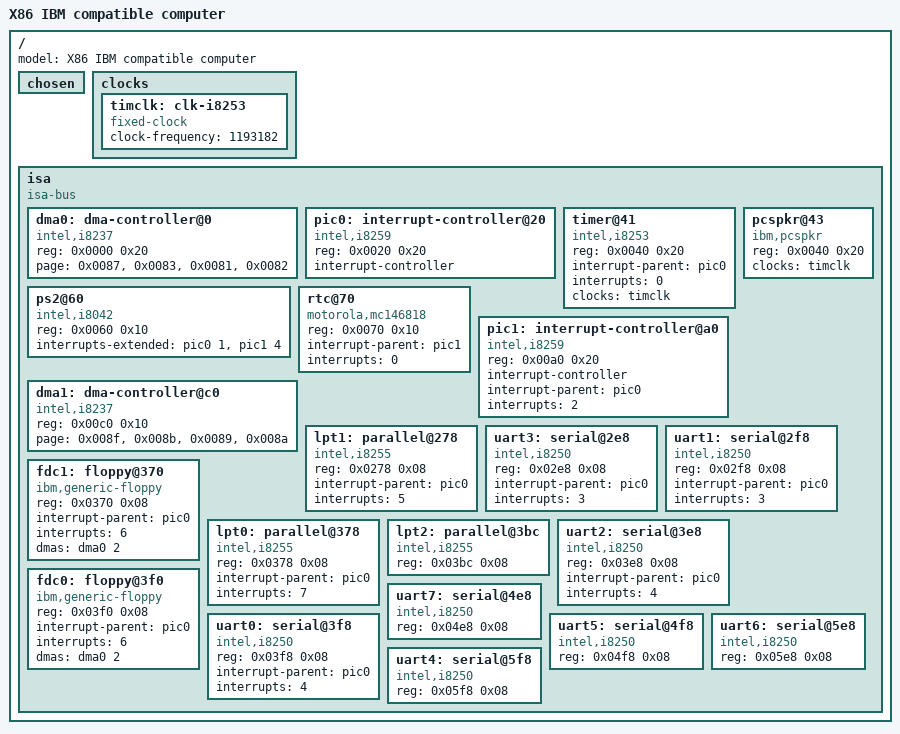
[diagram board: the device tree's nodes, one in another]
/* SPDX-License-Identifier: GPL-2.0-or-later */
/*
 * Copyright(c) 2021 John Sanpe <sanpeqf@gmail.com>
 */

/ {
    model = "X86 IBM compatible computer";
    #address-cells = <1>;
    #size-cells = <1>;

    chosen { };

    clocks {
        timclk: clk-i8253 {
            #clock-cells = <0>;
            compatible = "fixed-clock";
            clock-frequency = <1193182>;
        };
    };

    isa {
        #address-cells = <1>;
        #size-cells = <1>;
        compatible = "isa-bus";

        dma0: dma-controller@0 {
            #dma-cells = <1>;
            compatible = "intel,i8237";
            reg = <0x0000 0x20>;
            page = <0x0087>, <0x0083>,
                   <0x0081>, <0x0082>;
        };

        pic0: interrupt-controller@20 {
            #interrupt-cells = <1>;
            #address-cells = <0>;
            compatible = "intel,i8259";
            reg = <0x0020 0x20>;
            interrupt-controller;
        };

        timer@41 {
            compatible = "intel,i8253";
            reg = <0x0040 0x20>;
            interrupt-parent = <&pic0>;
            interrupts = <0>;
            clocks = <&timclk>;
        };

        pcspkr@43 {
            compatible = "ibm,pcspkr";
            reg = <0x0040 0x20>;
            clocks = <&timclk>;
        };

        ps2@60 {
            compatible = "intel,i8042";
            reg = <0x0060 0x10>;
            interrupt-names = "kbd", "aux";
            interrupts-extended = <&pic0 1>, <&pic1 4>;
        };

        rtc@70 {
            compatible = "motorola,mc146818";
            reg = <0x0070 0x10>;
            interrupt-parent = <&pic1>;
            interrupts = <0>;
        };

        pic1: interrupt-controller@a0 {
            #interrupt-cells = <1>;
            #address-cells = <0>;
            compatible = "intel,i8259";
            reg = <0x00a0 0x20>;
            interrupt-controller;
            interrupt-parent = <&pic0>;
            interrupts = <2>;
        };

        dma1: dma-controller@c0 {
            #dma-cells = <1>;
            compatible = "intel,i8237";
            reg = <0x00c0 0x10>;
            page = <0x008f>, <0x008b>,
                   <0x0089>, <0x008a>;
        };

        lpt1: parallel@278 {
            compatible = "intel,i8255";
            reg = <0x0278 0x08>;
            interrupt-parent = <&pic0>;
            interrupts = <5>;
            #address-cells = <1>;
            #size-cells = <0>;
        };

        uart3: serial@2e8 {
            compatible = "intel,i8250";
            reg = <0x02e8 0x08>;
            interrupt-parent = <&pic0>;
            interrupts = <3>;
        };

        uart1: serial@2f8 {
            compatible = "intel,i8250";
            reg = <0x02f8 0x08>;
            interrupt-parent = <&pic0>;
            interrupts = <3>;
        };

        fdc1: floppy@370 {
            compatible = "ibm,generic-floppy";
            reg = <0x0370 0x08>;
            interrupt-parent = <&pic0>;
            interrupts = <6>;
            dmas = <&dma0 2>;
        };

        lpt0: parallel@378 {
            compatible = "intel,i8255";
            reg = <0x0378 0x08>;
            interrupt-parent = <&pic0>;
            interrupts = <7>;
            #address-cells = <1>;
            #size-cells = <0>;
        };

        lpt2: parallel@3bc {
            compatible = "intel,i8255";
            reg = <0x03bc 0x08>;
            #address-cells = <1>;
            #size-cells = <0>;
        };

        uart2: serial@3e8 {
            compatible = "intel,i8250";
            reg = <0x03e8 0x08>;
            interrupt-parent = <&pic0>;
            interrupts = <4>;
        };

        fdc0: floppy@3f0 {
            compatible = "ibm,generic-floppy";
            reg = <0x03f0 0x08>;
            interrupt-parent = <&pic0>;
            interrupts = <6>;
            dmas = <&dma0 2>;
        };

        uart0: serial@3f8 {
            compatible = "intel,i8250";
            reg = <0x03f8 0x08>;
            interrupt-parent = <&pic0>;
            interrupts = <4>;
        };

        uart7: serial@4e8 {
            compatible = "intel,i8250";
            reg = <0x04e8 0x08>;
        };

        uart5: serial@4f8 {
            compatible = "intel,i8250";
            reg = <0x04f8 0x08>;
        };

        uart6: serial@5e8 {
            compatible = "intel,i8250";
            reg = <0x05e8 0x08>;
        };

        uart4: serial@5f8 {
            compatible = "intel,i8250";
            reg = <0x05f8 0x08>;
        };
    };
};
